# CY8C5888LTI_LP097 register map
File version: 0.1
Registers are 8-bit, read-write, no defined reset value unless marked. A register's access mark holds for its fields unless they carry their own. Offsets are from the block's base; [hi:lo] are bit positions; 'fields as' and 'values as' point back to an identical list.

## Lights_Out_1_LED_STATUS
Base 0x4000646A
0x00 Lights_Out_1_LED_STATUS_STATUS_REG
0x20 Lights_Out_1_LED_STATUS_MASK_REG
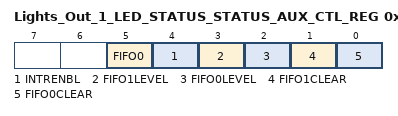
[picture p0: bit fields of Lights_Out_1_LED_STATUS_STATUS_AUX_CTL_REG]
0x30 Lights_Out_1_LED_STATUS_STATUS_AUX_CTL_REG
  [5] FIFO0 — FIFO0 clear
    1=ENABLED (Enable counter); 0=DISABLED (Disable counter)
  [4] INTRENBL — Enables or disables the Interrupt
    1=ENABLED (Interrupt enabled); 0=DISABLED (Interrupt disabled)
  [3] FIFO1LEVEL — FIFO level
    1=ENABLED (FIFO LVL: input mode: FIFO at least 1/2 empty; output mode: FIFO at least 1/2 full); 0=DISABLED (FIFO LVL: input mode: FIFO not full; output mode: FIFO not empty)
  [2] FIFO0LEVEL — FIFO level
    values as FIFO1LEVEL
  [1] FIFO1CLEAR — FIFO clear
    1=ENABLED (Clear FIFO state); 0=DISABLED (Normal FIFO operation)
  [0] FIFO0CLEAR — FIFO clear
    values as FIFO1CLEAR

## CROSSFADE_VAL
Base 0x40006564
Registers as Lights_Out_1_LED_STATUS (with Lights_Out_1_LED_STATUS read as CROSSFADE_VAL).

## LIGHT_BRIGHTNESS_5
Base 0x40006473
0x00 LIGHT_BRIGHTNESS_5_CONTROL_REG

## LIGHT_BRIGHTNESS_6
Base 0x40006477
Registers as LIGHT_BRIGHTNESS_5 (with LIGHT_BRIGHTNESS_5 read as LIGHT_BRIGHTNESS_6).

## LIGHT_BRIGHTNESS_7
Base 0x40006471
Registers as LIGHT_BRIGHTNESS_5 (with LIGHT_BRIGHTNESS_5 read as LIGHT_BRIGHTNESS_7).

## LIGHT_BRIGHTNESS_4
Base 0x40006475
Registers as LIGHT_BRIGHTNESS_5 (with LIGHT_BRIGHTNESS_5 read as LIGHT_BRIGHTNESS_4).

## LIGHT_BRIGHTNESS_1
Base 0x40006576
Registers as LIGHT_BRIGHTNESS_5 (with LIGHT_BRIGHTNESS_5 read as LIGHT_BRIGHTNESS_1).

## LIGHT_BRIGHTNESS_2
Base 0x40006578
Registers as LIGHT_BRIGHTNESS_5 (with LIGHT_BRIGHTNESS_5 read as LIGHT_BRIGHTNESS_2).

## LIGHT_BRIGHTNESS_3
Base 0x4000647C
Registers as LIGHT_BRIGHTNESS_5 (with LIGHT_BRIGHTNESS_5 read as LIGHT_BRIGHTNESS_3).

## HOT_LEDS
Base 0x40006478
Registers as LIGHT_BRIGHTNESS_5 (with LIGHT_BRIGHTNESS_5 read as HOT_LEDS).

## SLED_STATE_SEL
Base 0x40006479
Registers as LIGHT_BRIGHTNESS_5 (with LIGHT_BRIGHTNESS_5 read as SLED_STATE_SEL).

## CROSSFADE_CTRL
Base 0x40006574
Registers as LIGHT_BRIGHTNESS_5 (with LIGHT_BRIGHTNESS_5 read as CROSSFADE_CTRL).

## SleepTimer
Base 0x00000000
0x40004381 SleepTimer_CTW_INTERVAL_REG — Timewheel Configuration Register 1
  [3:0] ctw_interval — Sets the central timewheel interval.
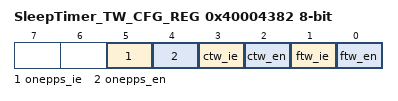
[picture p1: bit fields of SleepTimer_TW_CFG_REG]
0x40004382 SleepTimer_TW_CFG_REG — Timewheel Configuration Register 2
  [5] onepps_ie — When set and one pulse-per-second is enabled, an interrupt is issued when the pulse occurs.
    1=Enabled (One PPS interrupt is enabled); 0=Disabled (One PPS interrupt is disabled)
  [4] onepps_en — When set, the system returns to the active global power mode once every second.
    1=Enabled (One PPS is enabled); 0=Disabled (One PPS is disabled)
  [3] ctw_ie — When set and the central timewheel is enabled, an interrupt is issued when the central timewheel reaches the selected interval.
    1=Enabled (CTW interrupt is enabled); 0=Disabled (CTW interrupt is disabled)
  [2] ctw_en — When set, the system returns to the active global power mode when the central timewheel reaches the selected interval.
    1=Enabled (CTW is enabled); 0=Disabled (CTW is disabled)
  [1] ftw_ie — When set and the fast timewheel is enabled, an interrupt is issued when it reaches the terminal count.
    1=Enabled (FTW interrupt is enabled); 0=Disabled (FTW interrupt is disabled)
  [0] ftw_en — When set, the system returns to the active global power mode when the fast timewheel reaches the selected interval.
    1=Enabled (FTW is enabled); 0=Disabled (FTW is disabled)
